AUTOSAR XML (schema 4-2-1)
package /RootP_ASWC_A7D1
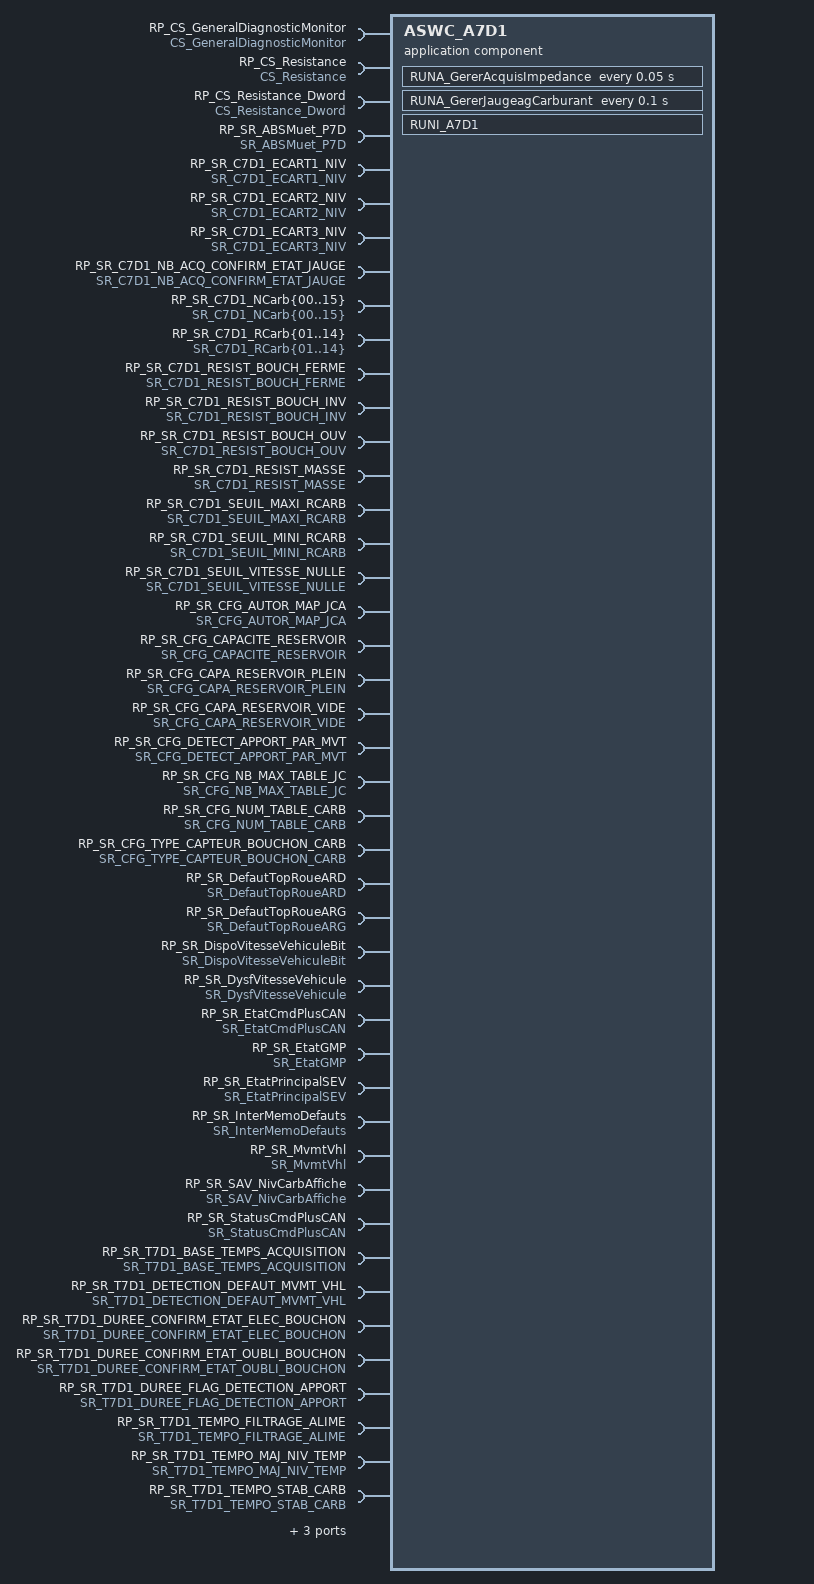
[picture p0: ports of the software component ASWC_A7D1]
  application sw component type ASWC_A7D1
    15 x provide/require port:
      PRP_SR_ApportCarbDetecte: nonqueued-receiver-com-spec{data-element=ApportCarbDetecte, enable-update=0, handle-data-status=1, handle-never-received=0, init-value=CONST_tLOG_0:0}, provided-required-interface=SR_ApportCarbDetecte
      PRP_SR_DefautBouchonCarbConfirme: nonqueued-receiver-com-spec{data-element=DefautBouchonCarbConfirme, enable-update=0, handle-data-status=1, handle-never-received=0, init-value=CONST_tLOG_0:0}, provided-required-interface=SR_DefautBouchonCarbConfirme
      PRP_SR_DefautJaugeCarbConfirme: nonqueued-receiver-com-spec{data-element=DefautJaugeCarbConfirme, enable-update=0, handle-data-status=1, handle-never-received=0, init-value=CONST_DefautJaugeCarbConfirme_t_cSDF_Defaut_cSDF_DefautAbsent:105}, provided-required-interface=SR_DefautJaugeCarbConfirme
      PRP_SR_DefautMvmtVhl: nonqueued-receiver-com-spec{data-element=DefautMvmtVhl, enable-update=0, handle-data-status=1, handle-never-received=0, init-value=CONST_tLOG_0:0}, provided-required-interface=SR_DefautMvmtVhl
      PRP_SR_DeltaCarb: nonqueued-receiver-com-spec{data-element=DeltaCarb, enable-update=0, handle-data-status=1, handle-never-received=0, init-value=CONST_tWORD_0:0}, provided-required-interface=SR_DeltaCarb
      PRP_SR_ImpedanceJaugeCarb: nonqueued-receiver-com-spec{data-element=ImpedanceJaugeCarb, enable-update=0, handle-data-status=1, handle-never-received=0, init-value=CONST_tDWORD_0:0}, provided-required-interface=SR_ImpedanceJaugeCarb
      PRP_SR_ModeDegrDefVitesse: nonqueued-receiver-com-spec{data-element=ModeDegrDefVitesse, enable-update=0, handle-data-status=1, handle-never-received=0, init-value=CONST_tLOG_0:0}, provided-required-interface=SR_ModeDegrDefVitesse
      PRP_SR_NivCarbBrutReference: nonqueued-receiver-com-spec{data-element=NivCarbBrutReference, enable-update=0, handle-data-status=1, handle-never-received=0, init-value=CONST_tWORD_0:0}, provided-required-interface=SR_NivCarbBrutReference
      PRP_SR_PbDetectionApport: nonqueued-receiver-com-spec{data-element=PbDetectionApport, enable-update=0, handle-data-status=1, handle-never-received=0, init-value=CONST_tLOG_0:0}, provided-required-interface=SR_PbDetectionApport
      PRP_SR_PremiereMesureJC_OK: nonqueued-receiver-com-spec{data-element=PremiereMesureJC_OK, enable-update=0, handle-data-status=1, handle-never-received=0, init-value=CONST_PremiereMesureJC_OK_t_cSDF_Mesure_cSDF_MesureNonRealisee:105}, provided-required-interface=SR_PremiereMesureJC_OK
      PRP_SR_SAV_DiagJaugeCarbu: nonqueued-receiver-com-spec{data-element=SAV_DiagJaugeCarbu, enable-update=0, handle-data-status=1, handle-never-received=0, init-value=CONST_SAV_DiagJaugeCarbu_t_Def_0_cAttenteDefJC:0}, provided-required-interface=SR_SAV_DiagJaugeCarbu
      PRP_SR_SAV_EtatBouchonCarb: nonqueued-receiver-com-spec{data-element=SAV_EtatBouchonCarb, enable-update=0, handle-data-status=1, handle-never-received=0, init-value=CONST_tLOG_0:0}, provided-required-interface=SR_SAV_EtatBouchonCarb
      PRP_SR_SAV_NivCarbMesure: nonqueued-receiver-com-spec{data-element=SAV_NivCarbMesure, enable-update=0, handle-data-status=1, handle-never-received=0, init-value=CONST_tWORD_0:0}, provided-required-interface=SR_SAV_NivCarbMesure
      PRP_SR_ToggleAcqJaugeRealisee: nonqueued-receiver-com-spec{data-element=ToggleAcqJaugeRealisee, enable-update=0, handle-data-status=1, handle-never-received=0, init-value=CONST_tLOG_0:0}, provided-required-interface=SR_ToggleAcqJaugeRealisee
      PRP_SR_ValiditeAbsenceBouchonCarb: nonqueued-receiver-com-spec{data-element=ValiditeAbsenceBouchonCarb, enable-update=0, handle-data-status=1, handle-never-received=0, init-value=CONST_tLOG_0:0}, provided-required-interface=SR_ValiditeAbsenceBouchonCarb
    75 x require port:
      RP_CS_GeneralDiagnosticMonitor: required-interface=CS_GeneralDiagnosticMonitor
      RP_CS_Resistance: required-interface=CS_Resistance
      RP_CS_Resistance_Dword: required-interface=CS_Resistance_Dword
      RP_SR_ABSMuet_P7D: nonqueued-receiver-com-spec{data-element=ABSMuet_P7D, enable-update=0, handle-data-status=1, handle-never-received=0, init-value=CONST_tLOG_0:0}, required-interface=SR_ABSMuet_P7D
      RP_SR_C7D1_ECART1_NIV: nonqueued-receiver-com-spec{data-element=C7D1_ECART1_NIV, enable-update=0, handle-data-status=1, handle-never-received=0, init-value=CONST_tWORD_5:5}, required-interface=SR_C7D1_ECART1_NIV
      RP_SR_C7D1_ECART2_NIV: nonqueued-receiver-com-spec{data-element=C7D1_ECART2_NIV, enable-update=0, handle-data-status=1, handle-never-received=0, init-value=CONST_tWORD_20:20}, required-interface=SR_C7D1_ECART2_NIV
      RP_SR_C7D1_ECART3_NIV: nonqueued-receiver-com-spec{data-element=C7D1_ECART3_NIV, enable-update=0, handle-data-status=1, handle-never-received=0, init-value=CONST_tWORD_10:10}, required-interface=SR_C7D1_ECART3_NIV
      RP_SR_C7D1_NB_ACQ_CONFIRM_ETAT_JAUGE: nonqueued-receiver-com-spec{data-element=C7D1_NB_ACQ_CONFIRM_ETAT_JAUGE, enable-update=0, handle-data-status=1, handle-never-received=0, init-value=CONST_tBYTE_8:8}, required-interface=SR_C7D1_NB_ACQ_CONFIRM_ETAT_JAUGE
      RP_SR_C7D1_NCarb{00..15}: nonqueued-receiver-com-spec{data-element=C7D1_NCarb{00..15}, enable-update=0, handle-data-status=1, handle-never-received=0, init-value=CONST_tBYTE_0:0}, required-interface=SR_C7D1_NCarb{00..15}
      RP_SR_C7D1_RCarb{01..14}: nonqueued-receiver-com-spec{data-element=C7D1_RCarb{01..14}, enable-update=0, handle-data-status=1, handle-never-received=0, init-value=CONST_tWORD_0:0}, required-interface=SR_C7D1_RCarb{01..14}
      RP_SR_C7D1_RESIST_BOUCH_FERME: nonqueued-receiver-com-spec{data-element=C7D1_RESIST_BOUCH_FERME, enable-update=0, handle-data-status=1, handle-never-received=0, init-value=CONST_tWORD_900:900}, required-interface=SR_C7D1_RESIST_BOUCH_FERME
      RP_SR_C7D1_RESIST_BOUCH_INV: nonqueued-receiver-com-spec{data-element=C7D1_RESIST_BOUCH_INV, enable-update=0, handle-data-status=1, handle-never-received=0, init-value=CONST_tWORD_500:500}, required-interface=SR_C7D1_RESIST_BOUCH_INV
      RP_SR_C7D1_RESIST_BOUCH_OUV: nonqueued-receiver-com-spec{data-element=C7D1_RESIST_BOUCH_OUV, enable-update=0, handle-data-status=1, handle-never-received=0, init-value=CONST_tWORD_100:100}, required-interface=SR_C7D1_RESIST_BOUCH_OUV
      RP_SR_C7D1_RESIST_MASSE: nonqueued-receiver-com-spec{data-element=C7D1_RESIST_MASSE, enable-update=0, handle-data-status=1, handle-never-received=0, init-value=CONST_tWORD_0:0}, required-interface=SR_C7D1_RESIST_MASSE
      RP_SR_C7D1_SEUIL_MAXI_RCARB: nonqueued-receiver-com-spec{data-element=C7D1_SEUIL_MAXI_RCARB, enable-update=0, handle-data-status=1, handle-never-received=0, init-value=CONST_tWORD_350:350}, required-interface=SR_C7D1_SEUIL_MAXI_RCARB
      RP_SR_C7D1_SEUIL_MINI_RCARB: nonqueued-receiver-com-spec{data-element=C7D1_SEUIL_MINI_RCARB, enable-update=0, handle-data-status=1, handle-never-received=0, init-value=CONST_tBYTE_50:50}, required-interface=SR_C7D1_SEUIL_MINI_RCARB
      RP_SR_C7D1_SEUIL_VITESSE_NULLE: nonqueued-receiver-com-spec{data-element=C7D1_SEUIL_VITESSE_NULLE, enable-update=0, handle-data-status=1, handle-never-received=0, init-value=CONST_tWORD_3:3}, required-interface=SR_C7D1_SEUIL_VITESSE_NULLE
      RP_SR_CFG_AUTOR_MAP_JCA: nonqueued-receiver-com-spec{data-element=CFG_AUTOR_MAP_JCA, enable-update=0, handle-data-status=1, handle-never-received=0, init-value=CONST_tLOG_0:0}, required-interface=SR_CFG_AUTOR_MAP_JCA
      RP_SR_CFG_CAPACITE_RESERVOIR: nonqueued-receiver-com-spec{data-element=CFG_CAPACITE_RESERVOIR, enable-update=0, handle-data-status=1, handle-never-received=0, init-value=CONST_tBYTE_50:50}, required-interface=SR_CFG_CAPACITE_RESERVOIR
      RP_SR_CFG_CAPA_RESERVOIR_PLEIN: nonqueued-receiver-com-spec{data-element=CFG_CAPA_RESERVOIR_PLEIN, enable-update=0, handle-data-status=1, handle-never-received=0, init-value=CONST_tWORD_80:80}, required-interface=SR_CFG_CAPA_RESERVOIR_PLEIN
      RP_SR_CFG_CAPA_RESERVOIR_VIDE: nonqueued-receiver-com-spec{data-element=CFG_CAPA_RESERVOIR_VIDE, enable-update=0, handle-data-status=1, handle-never-received=0, init-value=CONST_tWORD_320:320}, required-interface=SR_CFG_CAPA_RESERVOIR_VIDE
      RP_SR_CFG_DETECT_APPORT_PAR_MVT: nonqueued-receiver-com-spec{data-element=CFG_DETECT_APPORT_PAR_MVT, enable-update=0, handle-data-status=1, handle-never-received=0, init-value=CONST_tLOG_0:0}, required-interface=SR_CFG_DETECT_APPORT_PAR_MVT
      RP_SR_CFG_NB_MAX_TABLE_JC: nonqueued-receiver-com-spec{data-element=CFG_NB_MAX_TABLE_JC, enable-update=0, handle-data-status=1, handle-never-received=0, init-value=CONST_tBYTE_15:15}, required-interface=SR_CFG_NB_MAX_TABLE_JC
      RP_SR_CFG_NUM_TABLE_CARB: nonqueued-receiver-com-spec{data-element=CFG_NUM_TABLE_CARB, enable-update=0, handle-data-status=1, handle-never-received=0, init-value=CONST_tBYTE_255:255}, required-interface=SR_CFG_NUM_TABLE_CARB
      RP_SR_CFG_TYPE_CAPTEUR_BOUCHON_CARB: nonqueued-receiver-com-spec{data-element=CFG_TYPE_CAPTEUR_BOUCHON_CARB, enable-update=0, handle-data-status=1, handle-never-received=0, init-value=CONST_t_cCaptBouchon_0:0}, required-interface=SR_CFG_TYPE_CAPTEUR_BOUCHON_CARB
      RP_SR_DefautTopRoueARD: nonqueued-receiver-com-spec{data-element=DefautTopRoueARD, enable-update=0, handle-data-status=1, handle-never-received=0, init-value=CONST_tLOG_0:0}, required-interface=SR_DefautTopRoueARD
      RP_SR_DefautTopRoueARG: nonqueued-receiver-com-spec{data-element=DefautTopRoueARG, enable-update=0, handle-data-status=1, handle-never-received=0, init-value=CONST_tLOG_0:0}, required-interface=SR_DefautTopRoueARG
      RP_SR_DispoVitesseVehiculeBit: nonqueued-receiver-com-spec{data-element=DispoVitesseVehiculeBit, enable-update=0, handle-data-status=1, handle-never-received=0, init-value=CONST_tLOG_0:0}, required-interface=SR_DispoVitesseVehiculeBit
      RP_SR_DysfVitesseVehicule: nonqueued-receiver-com-spec{data-element=DysfVitesseVehicule, enable-update=0, handle-data-status=1, handle-never-received=0, init-value=CONST_t_cVitv_0:0}, required-interface=SR_DysfVitesseVehicule
      RP_SR_EtatCmdPlusCAN: nonqueued-receiver-com-spec{data-element=EtatCmdPlusCAN, enable-update=0, handle-data-status=1, handle-never-received=0, init-value=CONST_EtatCmdPlusCAN_t_cCMDPLUSCAN_cCMDPLUSCAN_INDETERMINE:3}, required-interface=SR_EtatCmdPlusCAN
      RP_SR_EtatGMP: nonqueued-receiver-com-spec{data-element=EtatGMP, enable-update=0, handle-data-status=1, handle-never-received=0, init-value=CONST_EtatGMP_t_GM_GMP_GM_GMPCoupe:1}, required-interface=SR_EtatGMP
      RP_SR_EtatPrincipalSEV: nonqueued-receiver-com-spec{data-element=EtatPrincipalSEV, enable-update=0, handle-data-status=1, handle-never-received=0, init-value=CONST_EtatPrincipalSEV_t_SEV_SEV_Arret:105}, required-interface=SR_EtatPrincipalSEV
      RP_SR_InterMemoDefauts: nonqueued-receiver-com-spec{data-element=InterMemoDefauts, enable-update=0, handle-data-status=1, handle-never-received=0, init-value=CONST_tLOG_0:0}, required-interface=SR_InterMemoDefauts
      RP_SR_MvmtVhl: nonqueued-receiver-com-spec{data-element=MvmtVhl, enable-update=0, handle-data-status=1, handle-never-received=0, init-value=CONST_tLOG_0:0}, required-interface=SR_MvmtVhl
      RP_SR_SAV_NivCarbAffiche: nonqueued-receiver-com-spec{data-element=SAV_NivCarbAffiche, enable-update=0, handle-data-status=1, handle-never-received=0, init-value=CONST_tWORD_0xFFFF:65535}, required-interface=SR_SAV_NivCarbAffiche
      RP_SR_StatusCmdPlusCAN: nonqueued-receiver-com-spec{data-element=StatusCmdPlusCAN, enable-update=0, handle-data-status=1, handle-never-received=0, init-value=CONST_StatusCmdPlusCAN_t_cCmdPlusCAN_PLUSCAN_UNDEFINED:3}, required-interface=SR_StatusCmdPlusCAN
      RP_SR_T7D1_BASE_TEMPS_ACQUISITION: nonqueued-receiver-com-spec{data-element=T7D1_BASE_TEMPS_ACQUISITION, enable-update=0, handle-data-status=1, handle-never-received=0, init-value=CONST_tWORD_250:250}, required-interface=SR_T7D1_BASE_TEMPS_ACQUISITION
      RP_SR_T7D1_DETECTION_DEFAUT_MVMT_VHL: nonqueued-receiver-com-spec{data-element=T7D1_DETECTION_DEFAUT_MVMT_VHL, enable-update=0, handle-data-status=1, handle-never-received=0, init-value=CONST_tBYTE_2:2}, required-interface=SR_T7D1_DETECTION_DEFAUT_MVMT_VHL
      RP_SR_T7D1_DUREE_CONFIRM_ETAT_ELEC_BOUCHON: nonqueued-receiver-com-spec{data-element=T7D1_DUREE_CONFIRM_ETAT_ELEC_BOUCHON, enable-update=0, handle-data-status=1, handle-never-received=0, init-value=CONST_tBYTE_2:2}, required-interface=SR_T7D1_DUREE_CONFIRM_ETAT_ELEC_BOUCHON
      RP_SR_T7D1_DUREE_CONFIRM_ETAT_OUBLI_BOUCHON: nonqueued-receiver-com-spec{data-element=T7D1_DUREE_CONFIRM_ETAT_OUBLI_BOUCHON, enable-update=0, handle-data-status=1, handle-never-received=0, init-value=CONST_tBYTE_2:2}, required-interface=SR_T7D1_DUREE_CONFIRM_ETAT_OUBLI_BOUCHON
      RP_SR_T7D1_DUREE_FLAG_DETECTION_APPORT: nonqueued-receiver-com-spec{data-element=T7D1_DUREE_FLAG_DETECTION_APPORT, enable-update=0, handle-data-status=1, handle-never-received=0, init-value=CONST_tBYTE_1:1}, required-interface=SR_T7D1_DUREE_FLAG_DETECTION_APPORT
      RP_SR_T7D1_TEMPO_FILTRAGE_ALIME: nonqueued-receiver-com-spec{data-element=T7D1_TEMPO_FILTRAGE_ALIME, enable-update=0, handle-data-status=1, handle-never-received=0, init-value=CONST_tWORD_500:500}, required-interface=SR_T7D1_TEMPO_FILTRAGE_ALIME
      RP_SR_T7D1_TEMPO_MAJ_NIV_TEMP: nonqueued-receiver-com-spec{data-element=T7D1_TEMPO_MAJ_NIV_TEMP, enable-update=0, handle-data-status=1, handle-never-received=0, init-value=CONST_tBYTE_2:2}, required-interface=SR_T7D1_TEMPO_MAJ_NIV_TEMP
      RP_SR_T7D1_TEMPO_STAB_CARB: nonqueued-receiver-com-spec{data-element=T7D1_TEMPO_STAB_CARB, enable-update=0, handle-data-status=1, handle-never-received=0, init-value=CONST_tBYTE_15:15}, required-interface=SR_T7D1_TEMPO_STAB_CARB
      RP_SR_VitesseVehicule: nonqueued-receiver-com-spec{data-element=VitesseVehicule, enable-update=0, handle-data-status=1, handle-never-received=0, init-value=CONST_tWORD_0:0}, required-interface=SR_VitesseVehicule
      RP_SR_VitesseVehiculeCorrompue: nonqueued-receiver-com-spec{data-element=VitesseVehiculeCorrompue, enable-update=0, handle-data-status=1, handle-never-received=0, init-value=CONST_tLOG_0:0}, required-interface=SR_VitesseVehiculeCorrompue
      ASWC_A7D1_MSI: required-interface=AppModeInterface
    behavior IB_ASWC_A7D1: data-type-mapping=ApplicationModeMapping, handle-termination-and-restart=NO-SUPPORT
      ar-typed-per-instance-memorys:
        68 x data:
          PA7D1_Accu{1..4}Mesures: type=tWORD, init-value=CONST_tWORD_0:0
          PA7D1_AutoriseCompParCle: type=tLOG, init-value=CONST_tLOG_0:0
          PA7D1_AutoStratCleBouch: type=tBYTE, init-value=CONST_tBYTE_0xC3:195
          PA7D1_CondMTPrec: type=tLOG, init-value=CONST_tLOG_0:0
          PA7D1_CondOubliBouch: type=tBILOG, init-value=CONST_tBILOG_0:0
          PA7D1_CondOubliBouchPrec: type=tBILOG, init-value=CONST_tBILOG_0:0
          PA7D1_CptConfDefCaptBouch: type=tBYTE, init-value=CONST_tBYTE_0:0
          PA7D1_CptConfDefOubliBouch: type=tBYTE, init-value=CONST_tBYTE_0:0
          PA7D1_CptConfEtatJaugeCarb: type=tBYTE, init-value=CONST_tBYTE_0:0
          PA7D1_CptFiltrageAlime: type=tBYTE, init-value=CONST_tBYTE_0:0
          PA7D1_CptTempoAppa_CapteurPresBouchon: type=tWORD, init-value=CONST_tWORD_0:0
          PA7D1_CptTempoAppa_JaugeCarburant: type=tWORD, init-value=CONST_tWORD_0:0
          PA7D1_CptTempoDisp_CapteurPresBouchon: type=tWORD, init-value=CONST_tWORD_0:0
          PA7D1_CptTempoDisp_JaugeCarburant: type=tWORD, init-value=CONST_tWORD_0:0
          PA7D1_DdeCompareNiv: type=tLOG, init-value=CONST_tLOG_0:0
          PA7D1_DefautElecBouchonCarb: type=t_cDEF_BOUCHCARB_ELEC, init-value=CONST_PA7D1_DefautElecBouchonCarb_t_cDEF_BOUCHCARB_ELEC_cDEF_BOUCHCARB_ELEC_NON_DIAG:0
          PA7D1_DefautElectriquePresent: type=tLOG, init-value=CONST_tLOG_0:0
          PA7D1_DefautJaugeCarb: type=t_cDEF_JAUGECARB, init-value=CONST_PA7D1_DefautJaugeCarb_t_cDEF_JAUGECARB_cDEF_JAUGECARB_NON_DIAG:0
          PA7D1_DefautMvmtVhl: type=tLOG, init-value=CONST_tLOG_0:0
          PA7D1_DefautOubliBouchConf: type=tLOG, init-value=CONST_tLOG_0:0
          PA7D1_DefautOubliBouchonCarb: type=tBILOG, init-value=CONST_tBILOG_0:0
          PA7D1_DefautPrec_CapteurPresBouchon: type=tBYTE, init-value=CONST_tBYTE_0:0
          PA7D1_DefautPrec_JaugeCarburant: type=tBYTE, init-value=CONST_tBYTE_0:0
          PA7D1_DefautTopRoues: type=tLOG, init-value=CONST_tLOG_0:0
          PA7D1_DefJCConfirmePrec: type=tBYTE, init-value=CONST_tBYTE_0x69:105
          PA7D1_DetAppCarbByBouch: type=tBYTE, init-value=CONST_tBYTE_0xC3:195
          PA7D1_EtatBouchonPourApport: type=tBILOG, init-value=CONST_tBILOG_2:2
          PA7D1_EtatBouchonRecue: type=tBILOG, init-value=CONST_tBILOG_0:0
          PA7D1_EtatBouchPourAppPrec: type=tBILOG, init-value=CONST_tBILOG_2:2
          PA7D1_EtatDerniereAcqJauge: type=tBILOG, init-value=CONST_tBILOG_0:0
          PA7D1_EtatDerniereAcqJPrec: type=tBILOG, init-value=CONST_tBILOG_0:0
          PA7D1_EtatGerNivCarbTem: type=tBYTE, init-value=CONST_tBYTE_0xC3:195
          PA7D1_EtatReelBouchCarbPrec: type=tBYTE, init-value=CONST_tBYTE_2:2
          PA7D1_EtatReelBouchonCarb: type=tBYTE, init-value=CONST_tBYTE_2:2
          PA7D1_EtatSysPrecEnAPC: type=tLOG, init-value=CONST_tLOG_0:0
          PA7D1_InterMemo: type=tLOG, init-value=CONST_tLOG_1:1
          PA7D1_InterMemoMvtMot: type=tLOG, init-value=CONST_tLOG_1:1
          PA7D1_MonteeDefaut_Mvmt: type=tBYTE, init-value=CONST_tBYTE_0:0
          PA7D1_MvmtVhlPrec: type=tLOG, init-value=CONST_tLOG_0:0
          PA7D1_NbAcquisitions: type=tBYTE, init-value=CONST_tBYTE_0:0
          PA7D1_NivCarbAfficheValide: type=tWORD, init-value=CONST_tWORD_0:0
          PA7D1_NivCarbMesureValide: type=tWORD, init-value=CONST_tWORD_0:0
          PA7D1_NivCarbTemp: type=tWORD, init-value=CONST_tWORD_0:0
          PA7D1_NivCarbTempPourComp: type=tWORD, init-value=CONST_tWORD_0:0
          PA7D1_OldStateDef2_CapteurPresBouchon: type=tBYTE, init-value=CONST_tBYTE_0:0
          PA7D1_OldStateDef2_JaugeCarburant: type=tBYTE, init-value=CONST_tBYTE_0:0
          PA7D1_PerteComRoues: type=tLOG, init-value=CONST_tLOG_0:0
          PA7D1_Prec_EtatSysteme: type=tBILOG, init-value=CONST_tBILOG_0:0
          PA7D1_ResistCapteurBouch: type=tWORD, init-value=CONST_tWORD_0:0
          PA7D1_ReveilBSIAvantFiltrage: type=tLOG, init-value=CONST_tLOG_1:1
          PA7D1_SAV_EspionNivCarbMesComp: type=tWORD, init-value=CONST_tWORD_0:0
          PA7D1_SAV_EspionNivCarbMesDetec: type=tWORD, init-value=CONST_tWORD_0:0
          PA7D1_SAV_NivCarbMesureMemo: type=tWORD, init-value=CONST_tWORD_0:0
          PA7D1_TempoAcquisition: type=tBYTE, init-value=CONST_tBYTE_0:0
          PA7D1_TogAcqJaugeRealPrec: type=tLOG, init-value=CONST_tLOG_0:0
          PA7D1_TombeeDefaut_Comm: type=tBYTE, init-value=CONST_tBYTE_0:0
          PA7D1_TombeeDefaut_MvmtARD: type=tBYTE, init-value=CONST_tBYTE_0:0
          PA7D1_TombeeDefaut_MvmtARG: type=tBYTE, init-value=CONST_tBYTE_0:0
          PA7D1_TpsFlagDetecteApport: type=tBYTE, init-value=CONST_tBYTE_0xFF:255
          PA7D1_TpsMAJNivTemp: type=tBYTE, init-value=CONST_tBYTE_0:0
          PA7D1_TpsStabCarbCle: type=tBYTE, init-value=CONST_tBYTE_0xFF:255
          PA7D1_TpsStabCarbMoteur: type=tBYTE, init-value=CONST_tBYTE_0xFF:255
          PA7D1_TpsStabCarbMouvement: type=tBYTE, init-value=CONST_tBYTE_0xFF:255
          PA7D1_TpsStabCarbVitesse: type=tBYTE, init-value=CONST_tBYTE_0xFF:255
          PA7D1_VitInfSeuilPrec: type=tLOG, init-value=CONST_tLOG_1:1
      timing event RUNA_GererAcquisImpedance_Cyclic: start-on-event=RUNA_GererAcquisImpedance, period=0.05
        disabled-mode:
          ASWC_A7D1_MSI.AppMode.APP_WAKEUP
          ASWC_A7D1_MSI.AppMode.APP_OFF
          ASWC_A7D1_MSI.AppMode.APP_SYNC_INIT
          ASWC_A7D1_MSI.AppMode.APP_CONFIG
      timing event RUNA_GererJaugeagCarburant_Cyclic: start-on-event=RUNA_GererJaugeagCarburant, period=0.1
        disabled-mode:
          ASWC_A7D1_MSI.AppMode.APP_WAKEUP
          ASWC_A7D1_MSI.AppMode.APP_OFF
          ASWC_A7D1_MSI.AppMode.APP_SYNC_INIT
          ASWC_A7D1_MSI.AppMode.APP_CONFIG
      swc mode switch event RUNI_A7D1_EXIT: start-on-event=RUNI_A7D1, activation=ON-EXIT, mode=ASWC_A7D1_MSI.AppMode.APP_WAKEUP
      explicit-inter-runnable-variables:
        data IRVA7D1_AlimeCapteurFiltree: type=tBYTE, init-value=CONST_tBYTE_0:0
        data IRVA7D1_DefautElecCaptBouchConf: type=tLOG, init-value=CONST_tLOG_0:0
      runnable RUNA_GererAcquisImpedance
        data-read-access:
          5 x access:
            dra_RP_SR_CFG_NB_MAX_TABLE_JC_CFG_NB_MAX_TABLE_JC: accessed-variable=RP_SR_CFG_NB_MAX_TABLE_JC.CFG_NB_MAX_TABLE_JC
            dra_RP_SR_CFG_NUM_TABLE_CARB_CFG_NUM_TABLE_CARB: accessed-variable=RP_SR_CFG_NUM_TABLE_CARB.CFG_NUM_TABLE_CARB
            dra_RP_SR_T7D1_BASE_TEMPS_ACQUISITION_T7D1_BASE_TEMPS_ACQUISITION: accessed-variable=RP_SR_T7D1_BASE_TEMPS_ACQUISITION.T7D1_BASE_TEMPS_ACQUISITION
            dra_PRP_SR_ImpedanceJaugeCarb_ImpedanceJaugeCarb: accessed-variable=PRP_SR_ImpedanceJaugeCarb.ImpedanceJaugeCarb
            dra_PRP_SR_ToggleAcqJaugeRealisee_ToggleAcqJaugeRealisee: accessed-variable=PRP_SR_ToggleAcqJaugeRealisee.ToggleAcqJaugeRealisee
        data-write-access:
          access dwa_PRP_SR_ImpedanceJaugeCarb_ImpedanceJaugeCarb: accessed-variable=PRP_SR_ImpedanceJaugeCarb.ImpedanceJaugeCarb
          access dwa_PRP_SR_ToggleAcqJaugeRealisee_ToggleAcqJaugeRealisee: accessed-variable=PRP_SR_ToggleAcqJaugeRealisee.ToggleAcqJaugeRealisee
        read-local-variables:
          access rlv_IRVA7D1_AlimeCapteurFiltree: accessed-variable=IRVA7D1_AlimeCapteurFiltree
        sync call sscp_RUNA_GererAcquisImpedance_CS_Resistance_Get: operation=RP_CS_Resistance.Get, timeout=0
      runnable RUNA_GererJaugeagCarburant
        data-read-access:
          83 x access:
            dra_PRP_SR_ToggleAcqJaugeRealisee_ToggleAcqJaugeRealisee: accessed-variable=PRP_SR_ToggleAcqJaugeRealisee.ToggleAcqJaugeRealisee
            dra_RP_SR_ABSMuet_P7D_ABSMuet_P7D: accessed-variable=RP_SR_ABSMuet_P7D.ABSMuet_P7D
            dra_RP_SR_DefautTopRoueARD_DefautTopRoueARD: accessed-variable=RP_SR_DefautTopRoueARD.DefautTopRoueARD
            dra_RP_SR_DefautTopRoueARG_DefautTopRoueARG: accessed-variable=RP_SR_DefautTopRoueARG.DefautTopRoueARG
            dra_RP_SR_DispoVitesseVehiculeBit_DispoVitesseVehiculeBit: accessed-variable=RP_SR_DispoVitesseVehiculeBit.DispoVitesseVehiculeBit
            dra_RP_SR_DysfVitesseVehicule_DysfVitesseVehicule: accessed-variable=RP_SR_DysfVitesseVehicule.DysfVitesseVehicule
            dra_RP_SR_EtatCmdPlusCAN_EtatCmdPlusCAN: accessed-variable=RP_SR_EtatCmdPlusCAN.EtatCmdPlusCAN
            dra_RP_SR_EtatGMP_EtatGMP: accessed-variable=RP_SR_EtatGMP.EtatGMP
            dra_RP_SR_EtatPrincipalSEV_EtatPrincipalSEV: accessed-variable=RP_SR_EtatPrincipalSEV.EtatPrincipalSEV
            dra_RP_SR_InterMemoDefauts_InterMemoDefauts: accessed-variable=RP_SR_InterMemoDefauts.InterMemoDefauts
            dra_RP_SR_MvmtVhl_MvmtVhl: accessed-variable=RP_SR_MvmtVhl.MvmtVhl
            dra_RP_SR_SAV_NivCarbAffiche_SAV_NivCarbAffiche: accessed-variable=RP_SR_SAV_NivCarbAffiche.SAV_NivCarbAffiche
            dra_RP_SR_StatusCmdPlusCAN_StatusCmdPlusCAN: accessed-variable=RP_SR_StatusCmdPlusCAN.StatusCmdPlusCAN
            dra_RP_SR_VitesseVehicule_VitesseVehicule: accessed-variable=RP_SR_VitesseVehicule.VitesseVehicule
            dra_RP_SR_VitesseVehiculeCorrompue_VitesseVehiculeCorrompue: accessed-variable=RP_SR_VitesseVehiculeCorrompue.VitesseVehiculeCorrompue
            dra_RP_SR_C7D1_ECART{1..3}_NIV_C7D1_ECART{1..3}_NIV: accessed-variable=RP_SR_C7D1_ECART{1..3}_NIV.C7D1_ECART{1..3}_NIV
            dra_RP_SR_C7D1_NB_ACQ_CONFIRM_ETAT_JAUGE_C7D1_NB_ACQ_CONFIRM_ETAT_JAUGE: accessed-variable=RP_SR_C7D1_NB_ACQ_CONFIRM_ETAT_JAUGE.C7D1_NB_ACQ_CONFIRM_ETAT_JAUGE
            dra_RP_SR_C7D1_NCarb{00..15}_C7D1_NCarb{00..15}: accessed-variable=RP_SR_C7D1_NCarb{00..15}.C7D1_NCarb{00..15}
            dra_RP_SR_C7D1_RCarb{01..14}_C7D1_RCarb{01..14}: accessed-variable=RP_SR_C7D1_RCarb{01..14}.C7D1_RCarb{01..14}
            dra_RP_SR_C7D1_RESIST_BOUCH_FERME_C7D1_RESIST_BOUCH_FERME: accessed-variable=RP_SR_C7D1_RESIST_BOUCH_FERME.C7D1_RESIST_BOUCH_FERME
            dra_RP_SR_C7D1_RESIST_BOUCH_INV_C7D1_RESIST_BOUCH_INV: accessed-variable=RP_SR_C7D1_RESIST_BOUCH_INV.C7D1_RESIST_BOUCH_INV
            dra_RP_SR_C7D1_RESIST_BOUCH_OUV_C7D1_RESIST_BOUCH_OUV: accessed-variable=RP_SR_C7D1_RESIST_BOUCH_OUV.C7D1_RESIST_BOUCH_OUV
            dra_RP_SR_C7D1_SEUIL_MAXI_RCARB_C7D1_SEUIL_MAXI_RCARB: accessed-variable=RP_SR_C7D1_SEUIL_MAXI_RCARB.C7D1_SEUIL_MAXI_RCARB
            dra_RP_SR_C7D1_SEUIL_MINI_RCARB_C7D1_SEUIL_MINI_RCARB: accessed-variable=RP_SR_C7D1_SEUIL_MINI_RCARB.C7D1_SEUIL_MINI_RCARB
            dra_RP_SR_C7D1_SEUIL_VITESSE_NULLE_C7D1_SEUIL_VITESSE_NULLE: accessed-variable=RP_SR_C7D1_SEUIL_VITESSE_NULLE.C7D1_SEUIL_VITESSE_NULLE
            dra_RP_SR_CFG_CAPACITE_RESERVOIR_CFG_CAPACITE_RESERVOIR: accessed-variable=RP_SR_CFG_CAPACITE_RESERVOIR.CFG_CAPACITE_RESERVOIR
            dra_RP_SR_CFG_CAPA_RESERVOIR_PLEIN_CFG_CAPA_RESERVOIR_PLEIN: accessed-variable=RP_SR_CFG_CAPA_RESERVOIR_PLEIN.CFG_CAPA_RESERVOIR_PLEIN
            dra_RP_SR_CFG_CAPA_RESERVOIR_VIDE_CFG_CAPA_RESERVOIR_VIDE: accessed-variable=RP_SR_CFG_CAPA_RESERVOIR_VIDE.CFG_CAPA_RESERVOIR_VIDE
            dra_RP_SR_CFG_DETECT_APPORT_PAR_MVT_CFG_DETECT_APPORT_PAR_MVT: accessed-variable=RP_SR_CFG_DETECT_APPORT_PAR_MVT.CFG_DETECT_APPORT_PAR_MVT
            dra_RP_SR_CFG_NB_MAX_TABLE_JC_CFG_NB_MAX_TABLE_JC: accessed-variable=RP_SR_CFG_NB_MAX_TABLE_JC.CFG_NB_MAX_TABLE_JC
            dra_RP_SR_CFG_NUM_TABLE_CARB_CFG_NUM_TABLE_CARB: accessed-variable=RP_SR_CFG_NUM_TABLE_CARB.CFG_NUM_TABLE_CARB
            dra_RP_SR_CFG_TYPE_CAPTEUR_BOUCHON_CARB_CFG_TYPE_CAPTEUR_BOUCHON_CARB: accessed-variable=RP_SR_CFG_TYPE_CAPTEUR_BOUCHON_CARB.CFG_TYPE_CAPTEUR_BOUCHON_CARB
            dra_RP_SR_T7D1_DETECTION_DEFAUT_MVMT_VHL_T7D1_DETECTION_DEFAUT_MVMT_VHL: accessed-variable=RP_SR_T7D1_DETECTION_DEFAUT_MVMT_VHL.T7D1_DETECTION_DEFAUT_MVMT_VHL
            dra_RP_SR_T7D1_DUREE_CONFIRM_ETAT_ELEC_BOUCHON_T7D1_DUREE_CONFIRM_ETAT_ELEC_BOUCHON: accessed-variable=RP_SR_T7D1_DUREE_CONFIRM_ETAT_ELEC_BOUCHON.T7D1_DUREE_CONFIRM_ETAT_ELEC_BOUCHON
            dra_RP_SR_T7D1_DUREE_CONFIRM_ETAT_OUBLI_BOUCHON_T7D1_DUREE_CONFIRM_ETAT_OUBLI_BOUCHON: accessed-variable=RP_SR_T7D1_DUREE_CONFIRM_ETAT_OUBLI_BOUCHON.T7D1_DUREE_CONFIRM_ETAT_OUBLI_BOUCHON
            dra_RP_SR_T7D1_DUREE_FLAG_DETECTION_APPORT_T7D1_DUREE_FLAG_DETECTION_APPORT: accessed-variable=RP_SR_T7D1_DUREE_FLAG_DETECTION_APPORT.T7D1_DUREE_FLAG_DETECTION_APPORT
            dra_RP_SR_T7D1_TEMPO_FILTRAGE_ALIME_T7D1_TEMPO_FILTRAGE_ALIME: accessed-variable=RP_SR_T7D1_TEMPO_FILTRAGE_ALIME.T7D1_TEMPO_FILTRAGE_ALIME
            dra_RP_SR_T7D1_TEMPO_MAJ_NIV_TEMP_T7D1_TEMPO_MAJ_NIV_TEMP: accessed-variable=RP_SR_T7D1_TEMPO_MAJ_NIV_TEMP.T7D1_TEMPO_MAJ_NIV_TEMP
            dra_RP_SR_T7D1_TEMPO_STAB_CARB_T7D1_TEMPO_STAB_CARB: accessed-variable=RP_SR_T7D1_TEMPO_STAB_CARB.T7D1_TEMPO_STAB_CARB
            dra_PRP_SR_ApportCarbDetecte_ApportCarbDetecte: accessed-variable=PRP_SR_ApportCarbDetecte.ApportCarbDetecte
            dra_PRP_SR_DefautBouchonCarbConfirme_DefautBouchonCarbConfirme: accessed-variable=PRP_SR_DefautBouchonCarbConfirme.DefautBouchonCarbConfirme
            dra_PRP_SR_DefautJaugeCarbConfirme_DefautJaugeCarbConfirme: accessed-variable=PRP_SR_DefautJaugeCarbConfirme.DefautJaugeCarbConfirme
            dra_PRP_SR_DefautMvmtVhl_DefautMvmtVhl: accessed-variable=PRP_SR_DefautMvmtVhl.DefautMvmtVhl
            dra_PRP_SR_DeltaCarb_DeltaCarb: accessed-variable=PRP_SR_DeltaCarb.DeltaCarb
            dra_PRP_SR_ImpedanceJaugeCarb_ImpedanceJaugeCarb: accessed-variable=PRP_SR_ImpedanceJaugeCarb.ImpedanceJaugeCarb
            dra_PRP_SR_ModeDegrDefVitesse_ModeDegrDefVitesse: accessed-variable=PRP_SR_ModeDegrDefVitesse.ModeDegrDefVitesse
            dra_PRP_SR_NivCarbBrutReference_NivCarbBrutReference: accessed-variable=PRP_SR_NivCarbBrutReference.NivCarbBrutReference
            dra_PRP_SR_PbDetectionApport_PbDetectionApport: accessed-variable=PRP_SR_PbDetectionApport.PbDetectionApport
            dra_PRP_SR_PremiereMesureJC_OK_PremiereMesureJC_OK: accessed-variable=PRP_SR_PremiereMesureJC_OK.PremiereMesureJC_OK
            dra_PRP_SR_SAV_DiagJaugeCarbu_SAV_DiagJaugeCarbu: accessed-variable=PRP_SR_SAV_DiagJaugeCarbu.SAV_DiagJaugeCarbu
            dra_PRP_SR_SAV_EtatBouchonCarb_SAV_EtatBouchonCarb: accessed-variable=PRP_SR_SAV_EtatBouchonCarb.SAV_EtatBouchonCarb
            dra_PRP_SR_SAV_NivCarbMesure_SAV_NivCarbMesure: accessed-variable=PRP_SR_SAV_NivCarbMesure.SAV_NivCarbMesure
            dra_PRP_SR_ValiditeAbsenceBouchonCarb_ValiditeAbsenceBouchonCarb: accessed-variable=PRP_SR_ValiditeAbsenceBouchonCarb.ValiditeAbsenceBouchonCarb
        data-write-access:
          14 x access:
            dwa_PRP_SR_ApportCarbDetecte_ApportCarbDetecte: accessed-variable=PRP_SR_ApportCarbDetecte.ApportCarbDetecte
            dwa_PRP_SR_DefautBouchonCarbConfirme_DefautBouchonCarbConfirme: accessed-variable=PRP_SR_DefautBouchonCarbConfirme.DefautBouchonCarbConfirme
            dwa_PRP_SR_DefautJaugeCarbConfirme_DefautJaugeCarbConfirme: accessed-variable=PRP_SR_DefautJaugeCarbConfirme.DefautJaugeCarbConfirme
            dwa_PRP_SR_DefautMvmtVhl_DefautMvmtVhl: accessed-variable=PRP_SR_DefautMvmtVhl.DefautMvmtVhl
            dwa_PRP_SR_DeltaCarb_DeltaCarb: accessed-variable=PRP_SR_DeltaCarb.DeltaCarb
            dwa_PRP_SR_ImpedanceJaugeCarb_ImpedanceJaugeCarb: accessed-variable=PRP_SR_ImpedanceJaugeCarb.ImpedanceJaugeCarb
            dwa_PRP_SR_ModeDegrDefVitesse_ModeDegrDefVitesse: accessed-variable=PRP_SR_ModeDegrDefVitesse.ModeDegrDefVitesse
            dwa_PRP_SR_NivCarbBrutReference_NivCarbBrutReference: accessed-variable=PRP_SR_NivCarbBrutReference.NivCarbBrutReference
            dwa_PRP_SR_PbDetectionApport_PbDetectionApport: accessed-variable=PRP_SR_PbDetectionApport.PbDetectionApport
            dwa_PRP_SR_PremiereMesureJC_OK_PremiereMesureJC_OK: accessed-variable=PRP_SR_PremiereMesureJC_OK.PremiereMesureJC_OK
            dwa_PRP_SR_SAV_DiagJaugeCarbu_SAV_DiagJaugeCarbu: accessed-variable=PRP_SR_SAV_DiagJaugeCarbu.SAV_DiagJaugeCarbu
            dwa_PRP_SR_SAV_EtatBouchonCarb_SAV_EtatBouchonCarb: accessed-variable=PRP_SR_SAV_EtatBouchonCarb.SAV_EtatBouchonCarb
            dwa_PRP_SR_SAV_NivCarbMesure_SAV_NivCarbMesure: accessed-variable=PRP_SR_SAV_NivCarbMesure.SAV_NivCarbMesure
            dwa_PRP_SR_ValiditeAbsenceBouchonCarb_ValiditeAbsenceBouchonCarb: accessed-variable=PRP_SR_ValiditeAbsenceBouchonCarb.ValiditeAbsenceBouchonCarb
        read-local-variables:
          access rlv_IRVA7D1_AlimeCapteurFiltree: accessed-variable=IRVA7D1_AlimeCapteurFiltree
          access rlv_IRVA7D1_DefautElecCaptBouchConf: accessed-variable=IRVA7D1_DefautElecCaptBouchConf
        sync call sscp_RUNA_GererJaugeagCarburant_CS_Resistance_Dword_Get: operation=RP_CS_Resistance_Dword.Get, timeout=0
        sync call sscp_RUNA_GererJaugeagCarburant_CS_GeneralDiagnosticMonitor_SetEventStatus: operation=RP_CS_GeneralDiagnosticMonitor.SetEventStatus, timeout=0
        written-local-variables:
          access wlv_IRVA7D1_AlimeCapteurFiltree: accessed-variable=IRVA7D1_AlimeCapteurFiltree
          access wlv_IRVA7D1_DefautElecCaptBouchConf: accessed-variable=IRVA7D1_DefautElecCaptBouchConf
      runnable RUNI_A7D1
        data-read-access:
          access dra_PRP_SR_DefautJaugeCarbConfirme_DefautJaugeCarbConfirme: accessed-variable=PRP_SR_DefautJaugeCarbConfirme.DefautJaugeCarbConfirme
          access dra_PRP_SR_DefautMvmtVhl_DefautMvmtVhl: accessed-variable=PRP_SR_DefautMvmtVhl.DefautMvmtVhl
        data-write-access:
          access dwa_PRP_SR_DefautJaugeCarbConfirme_DefautJaugeCarbConfirme: accessed-variable=PRP_SR_DefautJaugeCarbConfirme.DefautJaugeCarbConfirme
          access dwa_PRP_SR_DefautMvmtVhl_DefautMvmtVhl: accessed-variable=PRP_SR_DefautMvmtVhl.DefautMvmtVhl
        read-local-variables:
          access rlv_IRVA7D1_DefautElecCaptBouchConf: accessed-variable=IRVA7D1_DefautElecCaptBouchConf
        written-local-variables:
          access wlv_IRVA7D1_DefautElecCaptBouchConf: accessed-variable=IRVA7D1_DefautElecCaptBouchConf
package /RootP_Implementatation
  swc implementation Implementatation_ASWC_A7D1: programming-language=C, sw-version=1.0.0, vendor-id=1, behavior=IB_ASWC_A7D1
    code-descriptors:
      code SRC: artifact-descriptors=autosar-engineering-object={short-label=EngObject, category=SWSRC}
    resource consumption Resources
